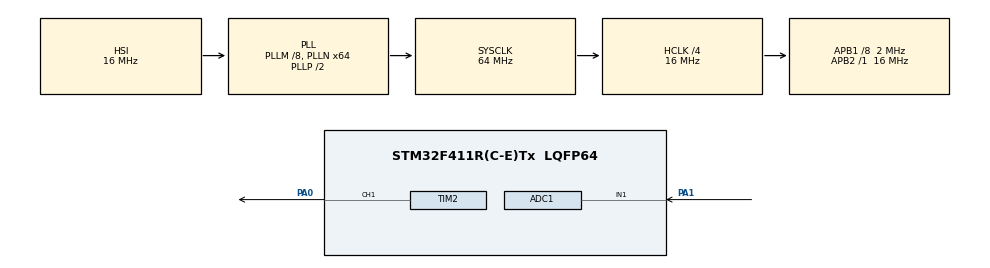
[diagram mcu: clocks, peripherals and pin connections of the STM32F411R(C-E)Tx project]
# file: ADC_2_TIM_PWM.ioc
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ADC1.Channel-2\#ChannelRegularConversion=ADC_CHANNEL_1
ADC1.NbrOfConversionFlag=1
ADC1.Rank-2\#ChannelRegularConversion=1
ADC1.SamplingTime-2\#ChannelRegularConversion=ADC_SAMPLETIME_3CYCLES
ADC1.master=1
Dma.Request0=TIM2_CH1
Dma.TIM2_CH1.0.Direction=DMA_PERIPH_TO_MEMORY
Dma.TIM2_CH1.0.FIFOMode=DMA_FIFOMODE_DISABLE
Dma.TIM2_CH1.0.Instance=DMA1_Stream5
Dma.TIM2_CH1.0.MemDataAlignment=DMA_MDATAALIGN_WORD
Dma.TIM2_CH1.0.MemInc=DMA_MINC_ENABLE
Dma.TIM2_CH1.0.Mode=DMA_NORMAL
Dma.TIM2_CH1.0.PeriphDataAlignment=DMA_PDATAALIGN_WORD
Dma.TIM2_CH1.0.PeriphInc=DMA_PINC_DISABLE
Dma.TIM2_CH1.0.Priority=DMA_PRIORITY_LOW
Mcu.Family=STM32F4
Mcu.Name=STM32F411R(C-E)Tx
Mcu.Package=LQFP64
NVIC.ADC_IRQn=true\:0\:0\:false\:false\:true\:true\:true\:true
NVIC.DMA1_Stream5_IRQn=true\:0\:0\:false\:false\:true\:false\:true\:true
NVIC.PriorityGroup=NVIC_PRIORITYGROUP_0
NVIC.RCC_IRQn=true\:0\:0\:false\:false\:true\:true\:false\:true
NVIC.TIM2_IRQn=true\:0\:0\:false\:false\:true\:true\:true\:true
PA0-WKUP.Signal=S_TIM2_CH1_ETR
PA1.Signal=ADCx_IN1
PA13.Mode=Serial_Wire
PA13.Signal=SYS_JTMS-SWDIO
PA14.Mode=Serial_Wire
PA14.Signal=SYS_JTCK-SWCLK
PH0\ -\ OSC_IN.Mode=HSE-External-Oscillator
PH0\ -\ OSC_IN.Signal=RCC_OSC_IN
PH1\ -\ OSC_OUT.Mode=HSE-External-Oscillator
PH1\ -\ OSC_OUT.Signal=RCC_OSC_OUT
ProjectManager.HeapSize=0x200
ProjectManager.StackSize=0x400
ProjectManager.TargetToolchain=STM32CubeIDE
RCC.48MHZClocksFreq_Value=32000000
RCC.AHBCLKDivider=RCC_SYSCLK_DIV4
RCC.AHBFreq_Value=16000000
RCC.APB1CLKDivider=RCC_HCLK_DIV8
RCC.APB1Freq_Value=2000000
RCC.APB1TimFreq_Value=4000000
RCC.APB2Freq_Value=16000000
RCC.APB2TimFreq_Value=16000000
RCC.CortexFreq_Value=16000000
RCC.FLatency-AdvancedSettings=FLASH_LATENCY_0
RCC.HCLKFreq_Value=16000000
RCC.HSE_VALUE=25000000
RCC.HSI_VALUE=16000000
RCC.LSE_VALUE=32768
RCC.PLLM=8
RCC.PLLN=64
RCC.SYSCLKFreq_VALUE=64000000
RCC.SYSCLKSource=RCC_SYSCLKSOURCE_PLLCLK
RCC.VCOOutputFreq_Value=128000000
SH.ADCx_IN1.0=ADC1_IN1,IN1
SH.S_TIM2_CH1_ETR.0=TIM2_CH1,PWM Generation1 CH1
TIM2.Channel-PWM\ Generation1\ CH1=TIM_CHANNEL_1
TIM2.Period=200
TIM2.Prescaler=2000-1
VP_TIM2_VS_ClockSourceINT.Mode=Internal
board=NUCLEO-F411RE

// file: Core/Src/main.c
/* USER CODE BEGIN Header */
/**
  ******************************************************************************
  * @file           : main.c
  * @brief          : Main program body
  ******************************************************************************
  * @attention
  *
  * Copyright (c) 2023 STMicroelectronics.
  * All rights reserved.
  * Este programa genera un PWM por el PIN_A0, utilizando el Timer2 como
  * base de tiempos, con los valores que tiene el Timer2 (CCR-ARR) genera una
  * frecuencia de 10Hz, y la relación techo-valle se varia con el potenciometro
  * que esta conectado al PIN_A1
  * This software is licensed under terms that can be found in the LICENSE file
  * in the root directory of this software component.
  * If no LICENSE file comes with this software, it is provided AS-IS.
  *
  ******************************************************************************
  */
/* USER CODE END Header */
#include "main.h"

ADC_HandleTypeDef hadc1;

TIM_HandleTypeDef htim2;
DMA_HandleTypeDef hdma_tim2_ch1;

void SystemClock_Config(void);
static void MX_GPIO_Init(void);
static void MX_DMA_Init(void);
static void MX_ADC1_Init(void);
static void MX_TIM2_Init(void);

/* USER CODE BEGIN 0 */
uint32_t dato_leido=0;
uint32_t Ciclo_Trabajo=0;
uint8_t PWM1=0;
/* USER CODE END 0 */

int main(void)
{

  /* MCU Configuration--------------------------------------------------------*/

  /* Reset of all peripherals, Initializes the Flash interface and the Systick. */
  HAL_Init();

  /* Configure the system clock */
  SystemClock_Config();

  /* Initialize all configured peripherals */
  MX_GPIO_Init();
  MX_DMA_Init();
  MX_ADC1_Init();
  MX_TIM2_Init();
  /* USER CODE BEGIN 2 */
  HAL_TIM_PWM_Start(&htim2, Ciclo_Trabajo);
  /* USER CODE END 2 */

  /* Infinite loop */
  while (1)
  {

    /* USER CODE BEGIN 3 */
	  HAL_ADC_Start(&hadc1);
	  	  	  HAL_ADC_PollForConversion(&hadc1, 10);
	  	  	  dato_leido = HAL_ADC_GetValue(&hadc1);
	  	  	  HAL_ADC_Stop(&hadc1);
	  	  	  Ciclo_Trabajo=(dato_leido)*200/4096;

	  	  	  __HAL_TIM_SET_COMPARE(&htim2, PWM1, Ciclo_Trabajo);

  }
  /* USER CODE END 3 */
}

void SystemClock_Config(void)
{
  RCC_OscInitTypeDef RCC_OscInitStruct = {0};
  RCC_ClkInitTypeDef RCC_ClkInitStruct = {0};

  /** Configure the main internal regulator output voltage
  */
  __HAL_RCC_PWR_CLK_ENABLE();
  __HAL_PWR_VOLTAGESCALING_CONFIG(PWR_REGULATOR_VOLTAGE_SCALE1);

  /** Initializes the RCC Oscillators according to the specified parameters
  * in the RCC_OscInitTypeDef structure.
  */
  RCC_OscInitStruct.OscillatorType = RCC_OSCILLATORTYPE_HSI;
  RCC_OscInitStruct.HSIState = RCC_HSI_ON;
  RCC_OscInitStruct.HSICalibrationValue = RCC_HSICALIBRATION_DEFAULT;
  RCC_OscInitStruct.PLL.PLLState = RCC_PLL_ON;
  RCC_OscInitStruct.PLL.PLLSource = RCC_PLLSOURCE_HSI;
  RCC_OscInitStruct.PLL.PLLM = 8;
  RCC_OscInitStruct.PLL.PLLN = 64;
  RCC_OscInitStruct.PLL.PLLP = RCC_PLLP_DIV2;
  RCC_OscInitStruct.PLL.PLLQ = 4;
  if (HAL_RCC_OscConfig(&RCC_OscInitStruct) != HAL_OK)
  {
    Error_Handler();
  }

  /** Initializes the CPU, AHB and APB buses clocks
  */
  RCC_ClkInitStruct.ClockType = RCC_CLOCKTYPE_HCLK|RCC_CLOCKTYPE_SYSCLK
                              |RCC_CLOCKTYPE_PCLK1|RCC_CLOCKTYPE_PCLK2;
  RCC_ClkInitStruct.SYSCLKSource = RCC_SYSCLKSOURCE_PLLCLK;
  RCC_ClkInitStruct.AHBCLKDivider = RCC_SYSCLK_DIV4;
  RCC_ClkInitStruct.APB1CLKDivider = RCC_HCLK_DIV8;
  RCC_ClkInitStruct.APB2CLKDivider = RCC_HCLK_DIV1;

  if (HAL_RCC_ClockConfig(&RCC_ClkInitStruct, FLASH_LATENCY_0) != HAL_OK)
  {
    Error_Handler();
  }
}

static void MX_ADC1_Init(void)
{

  ADC_ChannelConfTypeDef sConfig = {0};

  /** Configure the global features of the ADC (Clock, Resolution, Data Alignment and number of conversion)
  */
  hadc1.Instance = ADC1;
  hadc1.Init.ClockPrescaler = ADC_CLOCK_SYNC_PCLK_DIV2;
  hadc1.Init.Resolution = ADC_RESOLUTION_12B;
  hadc1.Init.ScanConvMode = DISABLE;
  hadc1.Init.ContinuousConvMode = DISABLE;
  hadc1.Init.DiscontinuousConvMode = DISABLE;
  hadc1.Init.ExternalTrigConvEdge = ADC_EXTERNALTRIGCONVEDGE_NONE;
  hadc1.Init.ExternalTrigConv = ADC_SOFTWARE_START;
  hadc1.Init.DataAlign = ADC_DATAALIGN_RIGHT;
  hadc1.Init.NbrOfConversion = 1;
  hadc1.Init.DMAContinuousRequests = DISABLE;
  hadc1.Init.EOCSelection = ADC_EOC_SINGLE_CONV;
  if (HAL_ADC_Init(&hadc1) != HAL_OK)
  {
    Error_Handler();
  }

  /** Configure for the selected ADC regular channel its corresponding rank in the sequencer and its sample time.
  */
  sConfig.Channel = ADC_CHANNEL_1;
  sConfig.Rank = 1;
  sConfig.SamplingTime = ADC_SAMPLETIME_3CYCLES;
  if (HAL_ADC_ConfigChannel(&hadc1, &sConfig) != HAL_OK)
  {
    Error_Handler();
  }

}

static void MX_TIM2_Init(void)
{

  TIM_ClockConfigTypeDef sClockSourceConfig = {0};
  TIM_MasterConfigTypeDef sMasterConfig = {0};
  TIM_OC_InitTypeDef sConfigOC = {0};

  htim2.Instance = TIM2;
  htim2.Init.Prescaler = 2000-1;
  htim2.Init.CounterMode = TIM_COUNTERMODE_UP;
  htim2.Init.Period = 200;
  htim2.Init.ClockDivision = TIM_CLOCKDIVISION_DIV1;
  htim2.Init.AutoReloadPreload = TIM_AUTORELOAD_PRELOAD_DISABLE;
  if (HAL_TIM_Base_Init(&htim2) != HAL_OK)
  {
    Error_Handler();
  }
  sClockSourceConfig.ClockSource = TIM_CLOCKSOURCE_INTERNAL;
  if (HAL_TIM_ConfigClockSource(&htim2, &sClockSourceConfig) != HAL_OK)
  {
    Error_Handler();
  }
  if (HAL_TIM_PWM_Init(&htim2) != HAL_OK)
  {
    Error_Handler();
  }
  sMasterConfig.MasterOutputTrigger = TIM_TRGO_RESET;
  sMasterConfig.MasterSlaveMode = TIM_MASTERSLAVEMODE_DISABLE;
  if (HAL_TIMEx_MasterConfigSynchronization(&htim2, &sMasterConfig) != HAL_OK)
  {
    Error_Handler();
  }
  sConfigOC.OCMode = TIM_OCMODE_PWM1;
  sConfigOC.Pulse = 0;
  sConfigOC.OCPolarity = TIM_OCPOLARITY_HIGH;
  sConfigOC.OCFastMode = TIM_OCFAST_DISABLE;
  if (HAL_TIM_PWM_ConfigChannel(&htim2, &sConfigOC, TIM_CHANNEL_1) != HAL_OK)
  {
    Error_Handler();
  }
  HAL_TIM_MspPostInit(&htim2);

}

static void MX_DMA_Init(void)
{

  /* DMA controller clock enable */
  __HAL_RCC_DMA1_CLK_ENABLE();

  /* DMA interrupt init */
  /* DMA1_Stream5_IRQn interrupt configuration */
  HAL_NVIC_SetPriority(DMA1_Stream5_IRQn, 0, 0);
  HAL_NVIC_EnableIRQ(DMA1_Stream5_IRQn);

}

static void MX_GPIO_Init(void)
{

  /* GPIO Ports Clock Enable */
  __HAL_RCC_GPIOH_CLK_ENABLE();
  __HAL_RCC_GPIOA_CLK_ENABLE();

}

void Error_Handler(void)
{
  __disable_irq();
  while (1)
  {
  }
}
